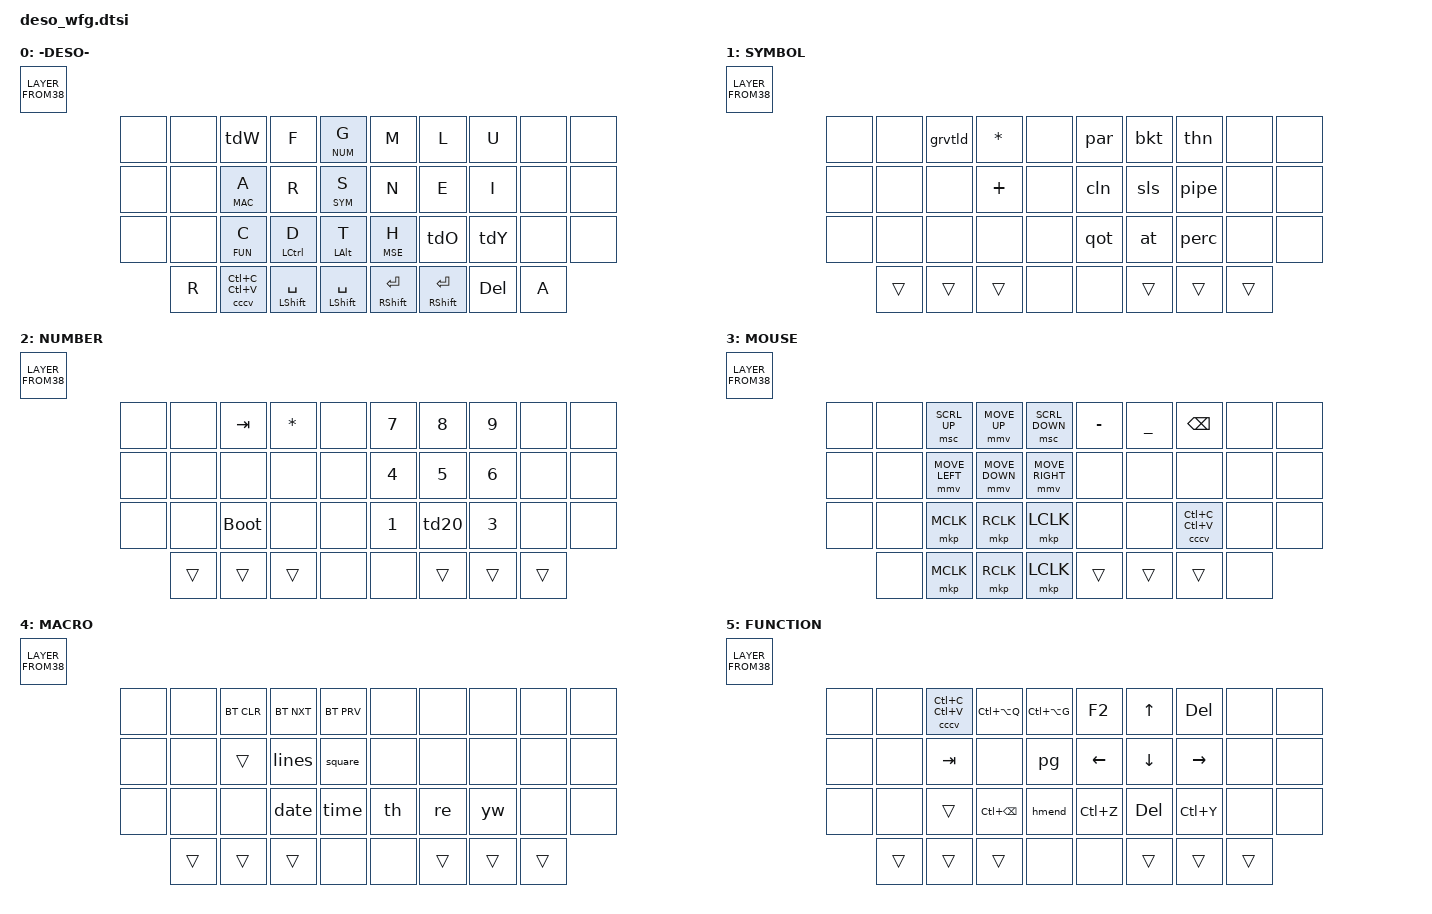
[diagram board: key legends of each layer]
/*
 * Last Update 10/5/24
 * WFG 19x2
 * 
 */
 
#include <behaviors.dtsi>
#include <dt-bindings/zmk/keys.h>
#include <dt-bindings/zmk/bt.h>
#include <dt-bindings/zmk/outputs.h>
#include <dt-bindings/zmk/mouse.h>
#include "combos_3col.dtsi"
#include "macros.dtsi"
#include "behaviors.dtsi"
#include "mouse.dtsi"
#    define MS_ACT(key) &lt MSE key

// Layer aliases
#define DEF 0
#define SYM 1
#define NUM 2
#define MSE 3
#define MAC 4
#define FUN 5

// Short defines
// #define D_LT   LC(LG(LEFT))
// #define D_RT   LC(LG(RIGHT))
// #define TAB_RT LC(TAB)
// #define TAB_LT LC(LS(TAB))
// #define LCC K_COPY
// #define LCV K_PASTE
#define SFTENT &mt RSHIFT RET
#define SFTSPC &mt LSHIFT SPC
#define CPST &cccv LC(C) LC(V)
#define CLIP &kp LC(LA(Q))
#define GSHT &kp LC(LA(G))

&mt {
    flavor = "hold-preferred";
    tapping-term-ms = <160>;
};

&lt {
    flavor = "balanced";
    tapping-term-ms = <150>;
};

/ {
   keymap {
        compatible = "zmk,keymap";


// ---------------------------------------------------------------------------------------------------------------
// |   TAB   |    W   [Q]   F   [B]   G num|         |    X    |         |    M   [J]   L    |    U    |  BSPC   |
// |  SHIFT  | A macro[V]   R   [P]   S sym|         |    X    |         |    N   [K]   E   [!]   I    |  DEL    |
// |  XXXX   |  C  fn [Z]   D   [X]   T    |         |    X    |         | H mouse |  O tt,  |  Y  tt. |  XXXX   |
//                     |   CCCV  |SPC/SHFT | RETURN  |    X    |   SPC   | SPC/ENT |   Paste |
// ---------------------------------------------------------------------------------------------------------------
        default_layer {
            display-name = "-DESO-";            
            bindings = <LAYER_FROM38( \
                &none, &none, &tdW, &kp F, &lt NUM G, &kp M, &kp L, &kp U, &none, &none, \
                &none, &none, &lt MAC A, &kp R, &lt SYM S, &kp N, &kp E, &kp I, &none, &none, \
                &none, &none, &lt FUN C, &hrm LCTRL D, &hrm LALT T, &lt MSE H, &tdO, &tdY, &none, &none, \
                &kp R, CPST,  SFTSPC, SFTSPC, SFTENT, SFTENT,  &kp DEL, &kp A \
            )>;
        };


        SYM_layer {
            display-name = "SYMBOL";
            bindings = <LAYER_FROM38( \
                &none, &none, &grvtld, &kp STAR, &none, &par, &bkt, &thn, &none, &none, \
                &none, &none, &none, &kp PLUS, &none, &cln, &sls, &pipe, &none, &none, \
                &none, &none, &none, &none, &none, &qot, &at, &perc, &none, &none, \
                &trans, &trans, &trans, &none, &none, &trans, &trans,  &trans \
            )>;
        };

        NUM_layer {
            display-name = "NUMBER";
            bindings = <LAYER_FROM38( \
                &none, &none, &kp TAB, &kp STAR, &none, &kp N7, &kp N8, &kp N9, &none, &none, \
                &none, &none, &none, &none, &none, &kp N4, &kp N5, &kp N6, &none, &none, \
                &none, &none, &bootloader, &none, &none, &kp N1, &td20, &kp N3, &none, &none, \
                       &trans, &trans, &trans, &none, &none, &trans, &trans, &trans \
            )>;
        };

        MOUSE_layer {
            display-name = "MOUSE";
            bindings = <LAYER_FROM38( \
                &none, &none, &msc SCRL_UP, &mmv MOVE_UP, &msc SCRL_DOWN, &kp MINUS, &kp UNDER, &kp BSPC, &none, &none, \
                &none, &none, &mmv MOVE_LEFT, &mmv MOVE_DOWN, &mmv MOVE_RIGHT, &none, &none, &none, &none, &none, \
                &none, &none, &mkp MCLK, &mkp RCLK, &mkp LCLK, &none, &none, CPST, &none, &none, \
                      &none, &mkp MCLK, &mkp RCLK, &mkp LCLK, &trans, &trans, &trans, &none \
            )>;
        };

        MACRO_layer {
            display-name = "MACRO";
            bindings = <LAYER_FROM38( \
                &none, &none, &bt BT_CLR, &bt BT_NXT,  &bt BT_PRV, &none, &none, &none, &none, &none, \
                &none, &none, &trans,     &lines, &square, &none, &none, &none, &none, &none, \
                &none, &none, &none,      &date,  &time, &th, &re, &yw, &none, &none, \
                      &trans, &trans, &trans, &none, &none, &trans, &trans, &trans \
            )>;
        };

        FN_layer {
            display-name = "FUNCTION";    
            bindings = <LAYER_FROM38( \
                &none, &none, CPST,    CLIP,  GSHT, &kp F2,   &kp UP,   &kp DEL, &none, &none, \
                &none, &none, &kp TAB, &none, &pg,  &kp LEFT, &kp DOWN, &kp RIGHT, &none, &none, \
                &none, &none, &trans, &kp LC(BSPC), &hmend, &kp LC(Z), &kp DEL, &kp LC(Y), &none, &none, \
                      &trans, &trans, &trans, &none, &none, &trans, &trans, &trans \
            )>;
        };
    };
};
